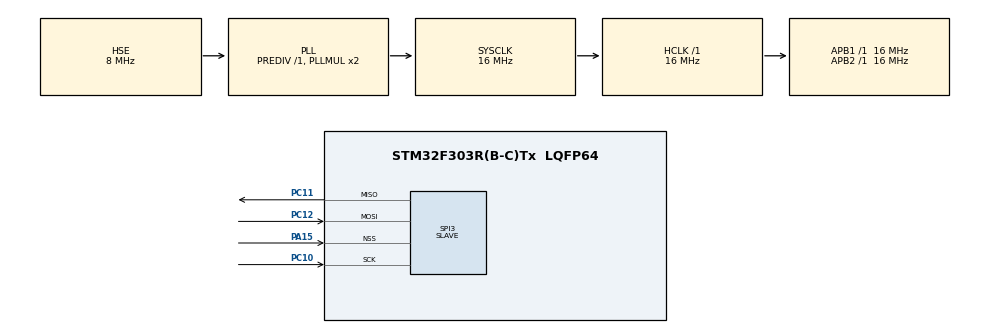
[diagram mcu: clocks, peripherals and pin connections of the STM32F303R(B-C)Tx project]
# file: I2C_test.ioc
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Mcu.Family=STM32F3
Mcu.Name=STM32F303R(B-C)Tx
Mcu.Package=LQFP64
NVIC.PriorityGroup=NVIC_PRIORITYGROUP_4
PA15.Mode=NSS_Signal_Hard_Input
PA15.Signal=SPI3_NSS
PC10.Mode=Full_Duplex_Slave
PC10.Signal=SPI3_SCK
PC11.Mode=Full_Duplex_Slave
PC11.Signal=SPI3_MISO
PC12.Mode=Full_Duplex_Slave
PC12.Signal=SPI3_MOSI
PF0-OSC_IN.Mode=HSE-External-Oscillator
PF0-OSC_IN.Signal=RCC_OSC_IN
PF1-OSC_OUT.Mode=HSE-External-Oscillator
PF1-OSC_OUT.Signal=RCC_OSC_OUT
ProjectManager.HeapSize=0x200
ProjectManager.StackSize=0x400
ProjectManager.TargetToolchain=STM32CubeIDE
RCC.AHBFreq_Value=16000000
RCC.APB1Freq_Value=16000000
RCC.APB1TimFreq_Value=16000000
RCC.APB2Freq_Value=16000000
RCC.APB2TimFreq_Value=16000000
RCC.CortexFreq_Value=16000000
RCC.HCLKFreq_Value=16000000
RCC.HSE_VALUE=8000000
RCC.HSI_VALUE=8000000
RCC.LSE_VALUE=32768
RCC.PLLSourceVirtual=RCC_PLLSOURCE_HSE
RCC.SYSCLKFreq_VALUE=16000000
RCC.SYSCLKSourceVirtual=RCC_SYSCLKSOURCE_PLLCLK
RCC.USBFreq_Value=16000000
SPI3.Direction=SPI_DIRECTION_2LINES
SPI3.Mode=SPI_MODE_SLAVE
SPI3.VirtualNSS=VM_NSSHARD
SPI3.VirtualType=VM_SLAVE
board=custom

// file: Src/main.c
/* USER CODE BEGIN Header */
/**
  ******************************************************************************
  * @file           : main.c
  * @brief          : Main program body
  ******************************************************************************
  * @attention
  *
  * <h2><center>&copy; Copyright (c) 2020 STMicroelectronics.
  * All rights reserved.</center></h2>
  *
  * This software component is licensed by ST under BSD 3-Clause license,
  * the "License"; You may not use this file except in compliance with the
  * License. You may obtain a copy of the License at:
  *                        opensource.org/licenses/BSD-3-Clause
  *
  ******************************************************************************
  */
/* USER CODE END Header */

#include "main.h"

/* USER CODE BEGIN Includes */
#include <string.h>
#include <stdio.h>
/* USER CODE END Includes */

SPI_HandleTypeDef hspi3;

/* USER CODE BEGIN PV */
uint8_t RxBuf[2] = {0};
/* USER CODE END PV */

void SystemClock_Config(void);
static void MX_GPIO_Init(void);
static void MX_SPI3_Init(void);

int main(void)
{
  /* USER CODE BEGIN 1 */
	uint16_t i = 0;
  /* USER CODE END 1 */

  /* MCU Configuration--------------------------------------------------------*/

  /* Reset of all peripherals, Initializes the Flash interface and the Systick. */
  HAL_Init();

  /* Configure the system clock */
  SystemClock_Config();

  /* Initialize all configured peripherals */
  MX_GPIO_Init();
  MX_SPI3_Init();

  /* Infinite loop */
  while (1)
  {

    /* USER CODE BEGIN 3 */
	    if(i<1) i=9999;
	    HAL_SPI_TransmitReceive(&hspi3, (uint8_t*) &i, (uint8_t *)RxBuf, 1, 5000);
	    i--;
  }

  /* USER CODE END 3 */
}

void SystemClock_Config(void)
{
  RCC_OscInitTypeDef RCC_OscInitStruct = {0};
  RCC_ClkInitTypeDef RCC_ClkInitStruct = {0};

  /** Initializes the CPU, AHB and APB busses clocks
  */
  RCC_OscInitStruct.OscillatorType = RCC_OSCILLATORTYPE_HSE;
  RCC_OscInitStruct.HSEState = RCC_HSE_ON;
  RCC_OscInitStruct.HSEPredivValue = RCC_HSE_PREDIV_DIV1;
  RCC_OscInitStruct.HSIState = RCC_HSI_ON;
  RCC_OscInitStruct.PLL.PLLState = RCC_PLL_ON;
  RCC_OscInitStruct.PLL.PLLSource = RCC_PLLSOURCE_HSE;
  RCC_OscInitStruct.PLL.PLLMUL = RCC_PLL_MUL2;
  if (HAL_RCC_OscConfig(&RCC_OscInitStruct) != HAL_OK)
  {
    Error_Handler();
  }
  /** Initializes the CPU, AHB and APB busses clocks
  */
  RCC_ClkInitStruct.ClockType = RCC_CLOCKTYPE_HCLK|RCC_CLOCKTYPE_SYSCLK
                              |RCC_CLOCKTYPE_PCLK1|RCC_CLOCKTYPE_PCLK2;
  RCC_ClkInitStruct.SYSCLKSource = RCC_SYSCLKSOURCE_PLLCLK;
  RCC_ClkInitStruct.AHBCLKDivider = RCC_SYSCLK_DIV1;
  RCC_ClkInitStruct.APB1CLKDivider = RCC_HCLK_DIV1;
  RCC_ClkInitStruct.APB2CLKDivider = RCC_HCLK_DIV1;

  if (HAL_RCC_ClockConfig(&RCC_ClkInitStruct, FLASH_LATENCY_0) != HAL_OK)
  {
    Error_Handler();
  }
}

static void MX_SPI3_Init(void)
{

  /* SPI3 parameter configuration*/
  hspi3.Instance = SPI3;
  hspi3.Init.Mode = SPI_MODE_SLAVE;
  hspi3.Init.Direction = SPI_DIRECTION_2LINES;
  hspi3.Init.DataSize = SPI_DATASIZE_4BIT;
  hspi3.Init.CLKPolarity = SPI_POLARITY_LOW;
  hspi3.Init.CLKPhase = SPI_PHASE_1EDGE;
  hspi3.Init.NSS = SPI_NSS_HARD_INPUT;
  hspi3.Init.FirstBit = SPI_FIRSTBIT_MSB;
  hspi3.Init.TIMode = SPI_TIMODE_DISABLE;
  hspi3.Init.CRCCalculation = SPI_CRCCALCULATION_DISABLE;
  hspi3.Init.CRCPolynomial = 7;
  hspi3.Init.CRCLength = SPI_CRC_LENGTH_DATASIZE;
  hspi3.Init.NSSPMode = SPI_NSS_PULSE_DISABLE;
  if (HAL_SPI_Init(&hspi3) != HAL_OK)
  {
    Error_Handler();
  }

}

static void MX_GPIO_Init(void)
{

  /* GPIO Ports Clock Enable */
  __HAL_RCC_GPIOF_CLK_ENABLE();
  __HAL_RCC_GPIOA_CLK_ENABLE();
  __HAL_RCC_GPIOC_CLK_ENABLE();

}

void Error_Handler(void)
{
}

/************************ (C) COPYRIGHT STMicroelectronics *****END OF FILE****/
